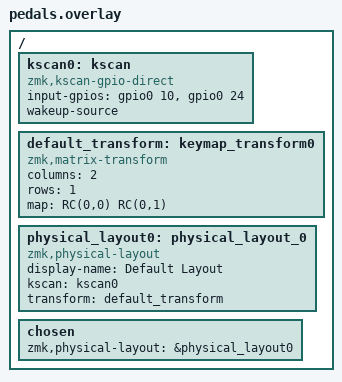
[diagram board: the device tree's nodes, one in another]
#include <dt-bindings/zmk/matrix_transform.h>


/ {
    kscan0: kscan {
        compatible = "zmk,kscan-gpio-direct";
        input-gpios = <&gpio0 10 (GPIO_ACTIVE_HIGH | GPIO_PULL_UP)>,
                      <&gpio0 24 (GPIO_ACTIVE_HIGH | GPIO_PULL_UP)>;
        wakeup-source;
    };
};
/ {
    default_transform: keymap_transform0 {
        compatible = "zmk,matrix-transform";
        columns = <2>; // Length of the "col-gpios" array
        rows = <1>; // Length of the "row-gpios" array
        map = <
        //   Key 1 | Key 2
            RC(0,0) RC(0,1)
        >;
    };
};
/ {
    physical_layout0: physical_layout_0 { // First physical layout, use different naming for other layouts
        compatible = "zmk,physical-layout";
        display-name = "Default Layout";
        kscan = <&kscan0>; // Label of the kscan node, optional if all layouts use the same
        transform = <&default_transform>; // Label of the matrix transform for this layout
    };
 };

/ {
    chosen {
        zmk,physical-layout = &physical_layout0;
        // Other chosen items
    };
};
